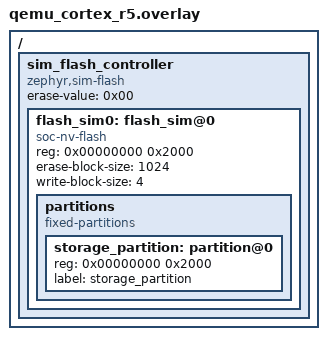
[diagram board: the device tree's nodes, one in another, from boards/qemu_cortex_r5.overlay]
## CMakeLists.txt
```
# Copyright (c) 2023 Intel Corporation.
# SPDX-License-Identifier: Apache-2.0

cmake_minimum_required(VERSION 3.28.0)
find_package(Zephyr REQUIRED HINTS $ENV{ZEPHYR_BASE})
project(llext_test)

target_sources(app PRIVATE
  src/test_llext.c
)

target_include_directories(app PRIVATE
  ${ZEPHYR_BASE}/include
  ${ZEPHYR_BASE}/kernel/include
  ${ZEPHYR_BASE}/arch/${ARCH}/include
)

set(ext_names
  hello_world
  logging
  relative_jump
  object
  syscalls
  inspect
  threads_kernel_objects
  export_dependent
  export_dependency
  align
)

if(CONFIG_ARM)
  if(NOT CONFIG_CPU_CORTEX_M0 AND NOT CONFIG_CPU_CORTEX_M0PLUS AND NOT CONFIG_CPU_CORTEX_M1)
    list(APPEND ext_names movwmovt)
  endif()
endif()

if(CONFIG_LLEXT_TYPE_ELF_RELOCATABLE AND NOT CONFIG_ARM)
    list(APPEND ext_names pre_located)
endif()

if(CONFIG_LLEXT_STORAGE_WRITABLE)
    list(APPEND ext_names find_section detached_fn)
endif()

if(NOT CONFIG_LLEXT_TYPE_ELF_SHAREDLIB)
    # ELF shared libraries do not support init sections
    list(APPEND ext_names init_fini)
endif()

if(CONFIG_LLEXT_RODATA_NO_RELOC AND NOT CONFIG_XTENSA)
    # Xtensa linker rejects relocations in .rodata even with -fPIC
    list(APPEND ext_names rodata_no_reloc)
endif()

if(CONFIG_XTENSA)
  # Only llext_link_plt(), used for all Xtensa relocations, accepts undefined weak symbols
  list(APPEND ext_names weak_undef)
endif()

# generate extension targets for each extension in 'ext_names'
foreach(ext_name ${ext_names})
  set(ext_src ${PROJECT_SOURCE_DIR}/src/${ext_name}_ext.c)
  set(ext_bin ${PROJECT_BINARY_DIR}/llext/${ext_name}.llext)
  set(ext_inc ${ZEPHYR_BINARY_DIR}/include/generated/${ext_name}.inc)
  add_llext_target(${ext_name}_ext
    OUTPUT  ${ext_bin}
    SOURCES ${ext_src}
  )
  generate_inc_file_for_target(app ${ext_bin} ${ext_inc})
endforeach()

if(CONFIG_LLEXT_VENEERS)
  set(ext_bin ${PROJECT_BINARY_DIR}/llext/veneer.llext)
  set(ext_inc ${ZEPHYR_BINARY_DIR}/include/generated/veneer.inc)
  add_llext_target(veneer_ext
    OUTPUT  ${ext_bin}
    SOURCES ${PROJECT_SOURCE_DIR}/src/veneer_ext.c
  )
  # -mno-long-calls overrides the global -mlong-calls so direct BL instructions
  # are emitted, producing R_ARM_THM_CALL relocations that exercise the veneer.
  get_target_property(veneer_lib veneer_ext lib_target)
  target_compile_options(${veneer_lib} PRIVATE -mno-long-calls)
  generate_inc_file_for_target(app ${ext_bin} ${ext_inc})
endif()

# C++ extensions exercising virtual dispatch, vtable relocations and weak
# symbols emitted for C++ code
if(CONFIG_CPP)
  function(add_cpp_llext_test ext_name)
    list(TRANSFORM ARGN PREPEND ${PROJECT_SOURCE_DIR}/src/)
    add_llext_target(${ext_name}_ext
      OUTPUT  ${PROJECT_BINARY_DIR}/llext/${ext_name}.llext
      SOURCES ${ARGN}
    )
    get_target_property(ext_lib ${ext_name}_ext lib_target)
    target_compile_options(${ext_lib} PRIVATE
      $<$<COMPILE_LANGUAGE:CXX>:-std=c++17>
      -fno-rtti
      -fno-exceptions
    )
    generate_inc_file_for_target(app ${PROJECT_BINARY_DIR}/llext/${ext_name}.llext
      ${ZEPHYR_BINARY_DIR}/include/generated/${ext_name}.inc
    )
  endfunction()

  add_cpp_llext_test(weak_vtable weak_vtable_ext.cpp)
  add_cpp_llext_test(cpp_dispatch cpp_dispatch_ext.cpp)
  add_cpp_llext_test(cpp_multi_tu cpp_multi_tu_ext1.cpp cpp_multi_tu_ext2.cpp)
endif()

# An extension referencing the thread-local errno, exercising the AArch64
# local-exec TLS relocations (R_AARCH64_TLSLE_ADD_TPREL_*). Only arm64
# implements these in arch_elf_relocate(); a libc whose errno is genuinely
# __thread (toolchain picolibc with thread-local storage) is enabled by the
# llext.tls scenario.
if(CONFIG_ARM64 AND CONFIG_THREAD_LOCAL_STORAGE)
  add_llext_target(tls_ext
    OUTPUT  ${PROJECT_BINARY_DIR}/llext/tls.llext
    SOURCES ${PROJECT_SOURCE_DIR}/src/tls_ext.c
  )
  generate_inc_file_for_target(app ${PROJECT_BINARY_DIR}/llext/tls.llext
    ${ZEPHYR_BINARY_DIR}/include/generated/tls.inc
  )
endif()

if(NOT CONFIG_LLEXT_TYPE_ELF_OBJECT)
  add_llext_target(multi_file_ext
    OUTPUT  ${PROJECT_BINARY_DIR}/llext/multi_file.llext
    SOURCES ${PROJECT_SOURCE_DIR}/src/multi_file_ext1.c ${PROJECT_SOURCE_DIR}/src/multi_file_ext2.c
  )
  generate_inc_file_for_target(app ${PROJECT_BINARY_DIR}/llext/multi_file.llext
    ${ZEPHYR_BINARY_DIR}/include/generated/multi_file.inc
  )
endif()

get_property(TOPT GLOBAL PROPERTY TOPT)
get_property(COMPILER_TOPT TARGET compiler PROPERTY linker_script)
set_ifndef(  TOPT "${COMPILER_TOPT}")
set_ifndef(  TOPT -Wl,-T) # Use this if the compiler driver doesn't set a value

if(CONFIG_LLEXT_TYPE_ELF_RELOCATABLE AND CONFIG_XTENSA AND CONFIG_LLEXT_STORAGE_WRITABLE)
  # Manually fix the pre_located extension's text address at a multiple of 4
  get_target_property(pre_located_target pre_located_ext lib_target)
  get_target_property(pre_located_file pre_located_ext pkg_input)
  add_llext_command(
    TARGET pre_located_ext
    POST_BUILD
    COMMAND ${CMAKE_C_COMPILER}
    ${LLEXT_APPEND_FLAGS}
    -Wl,-r ${TOPT}text=0xbada110c -nostdlib -nodefaultlibs -nostartfiles
    $<TARGET_OBJECTS:${pre_located_target}> -o ${pre_located_file}
  )
endif()

if(CONFIG_LLEXT_TYPE_ELF_RELOCATABLE AND CONFIG_XTENSA)
  # A copy of hello_world with a relocation offset past the end of .text
  set(ext_bin ${PROJECT_BINARY_DIR}/llext/reloc_offset_oob.llext)
  add_custom_command(
    OUTPUT ${ext_bin}
    COMMAND ${PYTHON_EXECUTABLE} ${PROJECT_SOURCE_DIR}/reloc_offset_oob.py
            ${PROJECT_BINARY_DIR}/llext/hello_world.llext ${ext_bin}
    DEPENDS ${PROJECT_BINARY_DIR}/llext/hello_world.llext
            ${PROJECT_SOURCE_DIR}/reloc_offset_oob.py
  )
  generate_inc_file_for_target(app ${ext_bin}
    ${ZEPHYR_BINARY_DIR}/include/generated/reloc_offset_oob.inc
  )
endif()

if(NOT CONFIG_LLEXT_TYPE_ELF_OBJECT AND CONFIG_RISCV AND CONFIG_RISCV_ISA_EXT_C)
  add_llext_target(riscv_edge_case_cb_type_ext
    OUTPUT  ${PROJECT_BINARY_DIR}/llext/riscv_edge_case_cb_type_ext.llext
    SOURCES ${PROJECT_SOURCE_DIR}/src/riscv_edge_case_cb_type.c ${PROJECT_SOURCE_DIR}/src/riscv_edge_case_cb_type_trigger.S
  )
  generate_inc_file_for_target(app ${PROJECT_BINARY_DIR}/llext/riscv_edge_case_cb_type_ext.llext
    ${ZEPHYR_BINARY_DIR}/include/generated/riscv_edge_case_cb_type.inc
  )
endif()

if(NOT CONFIG_LLEXT_TYPE_ELF_OBJECT AND CONFIG_RISCV)
  add_llext_target(riscv_edge_case_non_paired_hi20_lo12_ext
    OUTPUT  ${PROJECT_BINARY_DIR}/llext/riscv_edge_case_non_paired_hi20_lo12_ext.llext
    SOURCES ${PROJECT_SOURCE_DIR}/src/riscv_edge_case_non_paired_hi20_lo12.c ${PROJECT_SOURCE_DIR}/src/riscv_edge_case_non_paired_hi20_lo12_trigger.S
  )
  generate_inc_file_for_target(app ${PROJECT_BINARY_DIR}/llext/riscv_edge_case_non_paired_hi20_lo12_ext.llext
    ${ZEPHYR_BINARY_DIR}/include/generated/riscv_edge_case_non_paired_hi20_lo12.inc
  )
endif()
```

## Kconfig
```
# SPDX-License-Identifier: Apache-2.0
# Copyright (c) 2025 Intel Corporation.

mainmenu "LLEXT tests"

config MP_MAX_NUM_CPUS
	default 1 if LLEXT_READONLY_1CPU

source "Kconfig.zephyr"

config LLEXT_INC_IN_TEXT
	bool "Put extension .inc array in .text instead of .data"
	help
	  Put the llext extension .inc arrays from the LLEXT subsys tests
	  in .text instead of .data by default. This is useful for when the
	  memory region the linker places .data in by default is not suitable
	  for execution.

config LLEXT_READONLY_1CPU
	bool "Enable this when using readonly elf buffer on 1 CPU"
	depends on SOC_SERIES_INTEL_ADSP_ACE20 || \
		SOC_SERIES_INTEL_ADSP_ACE30 || \
		SOC_SERIES_INTEL_ADSP_ACE40
	select LLEXT_CUSTOM_HEAP_PLACEMENT
```

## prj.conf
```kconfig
CONFIG_ZTEST=y
CONFIG_ZTEST_STACK_SIZE=4096
CONFIG_LOG=y
CONFIG_LLEXT=y
CONFIG_LLEXT_HEAP_SIZE=64
CONFIG_LLEXT_EXPORT_DEVICES=y

CONFIG_APPLICATION_DEFINED_SYSCALL=y

# RISC-V copies the loaded extension into RAM and runs it in machine
# mode, so the loaded text must stay executable. Data execution
# prevention installs a locked catch-all PMP entry that makes all RAM
# non-executable, which faults on the first call into an extension.
# Setting an unknown symbol to 'n' has no effect, so this is safe on
# the other architectures.
CONFIG_PMP_DATA_EXECUTION_PREVENTION=n

# The bulk of the tests run with MPU/MMU disabled by including additional
# configuration entries from no_mem_protection.conf.
```

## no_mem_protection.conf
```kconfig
# Disable MPU and MMU on all supported arches for the bulk of the tests.
#
# This uses the fact that setting an unknown symbol to 'n' has no effect,
# so it is safe to group different arch-specific settings here.
#
CONFIG_ARM_MPU=n
CONFIG_ARM_AARCH32_MMU=n
CONFIG_RISCV_PMP=n
CONFIG_ARC_MPU_ENABLE=n
CONFIG_X86_MMU=n
```

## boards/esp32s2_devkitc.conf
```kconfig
CONFIG_SYS_HEAP_BIG_ONLY=y
```

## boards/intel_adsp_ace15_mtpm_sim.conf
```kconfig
# xt-clang cannot link shared libs for xtensa
CONFIG_LLEXT_TYPE_ELF_RELOCATABLE=y
```

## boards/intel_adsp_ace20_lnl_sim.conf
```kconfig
# xt-clang cannot link shared libs for xtensa
CONFIG_LLEXT_TYPE_ELF_RELOCATABLE=y
CONFIG_LLEXT_INC_IN_TEXT=y
```

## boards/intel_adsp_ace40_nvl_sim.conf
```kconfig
# xt-clang cannot link shared libs for xtensa
CONFIG_LLEXT_TYPE_ELF_RELOCATABLE=y
CONFIG_LLEXT_INC_IN_TEXT=y
CONFIG_LLEXT_CUSTOM_HEAP_PLACEMENT=y
```

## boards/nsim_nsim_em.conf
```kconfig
CONFIG_LLEXT_INSTR_HEAP_SIZE=16
CONFIG_LLEXT_DATA_HEAP_SIZE=48
```

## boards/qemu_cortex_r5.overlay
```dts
/ {
	sim_flash_controller: sim_flash_controller {
		compatible = "zephyr,sim-flash";

		#address-cells = <1>;
		#size-cells = <1>;
		erase-value = <0x00>;

		flash_sim0: flash_sim@0 {
			compatible = "soc-nv-flash";
			reg = <0x00000000 0x2000>;

			erase-block-size = <1024>;
			write-block-size = <4>;

			partitions {
				compatible = "fixed-partitions";
				#address-cells = <1>;
				#size-cells = <1>;

				storage_partition: partition@0 {
					reg = <0x00000000 0x2000>;
					label = "storage_partition";
				};
			};
		};
	};
};
```

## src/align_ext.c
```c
/*
 * Copyright (c) 2025 Arduino SA
 *
 * SPDX-License-Identifier: Apache-2.0
 */

/*
 * Define symbols with different alignment requirements and verify that LLEXT
 * correctly handles them by testing the runtime address and the contents of
 * each defined symbol.
 */

#include <stdint.h>
#include <zephyr/kernel.h>
#include <zephyr/llext/symbol.h>
#include <zephyr/ztest_assert.h>

/*
 * Create constants requesting a specific alignment in memory and with a value
 * that is related but not equal to their alignment requirement.
 */
#define ALIGNED_ENTRY(name, n) \
	 const int name ## _ ## n __aligned(n) = n / 2 + 1

ALIGNED_ENTRY(common, 8);
ALIGNED_ENTRY(common, 16);
ALIGNED_ENTRY(common, 32);
ALIGNED_ENTRY(common, 64);
ALIGNED_ENTRY(common, 128);
ALIGNED_ENTRY(common, 256);
ALIGNED_ENTRY(common, 512);

/*
 * Create similar constants in a set of independent sections to test merging.
 */
#define ALIGNED_SECT_ENTRY(name, n) \
	Z_GENERIC_SECTION(name ## _sect_ ## n) ALIGNED_ENTRY(name, n)

ALIGNED_SECT_ENTRY(independent, 8);
ALIGNED_SECT_ENTRY(independent, 16);
ALIGNED_SECT_ENTRY(independent, 32);
ALIGNED_SECT_ENTRY(independent, 64);
ALIGNED_SECT_ENTRY(independent, 128);
ALIGNED_SECT_ENTRY(independent, 256);
ALIGNED_SECT_ENTRY(independent, 512);

/*
 * Test that each symbol matches its expected value and alignment.
 */
#define ASSERT_ENTRY(name, n) \
	zassert_equal(name ## _ ## n, n / 2 + 1); \
	zassert_true(IS_ALIGNED(&name ## _ ## n, n))

void test_entry(void)
{
	ASSERT_ENTRY(common, 8);
	ASSERT_ENTRY(common, 16);
	ASSERT_ENTRY(common, 32);
	ASSERT_ENTRY(common, 64);
	ASSERT_ENTRY(common, 128);
	ASSERT_ENTRY(common, 256);
	ASSERT_ENTRY(common, 512);

	ASSERT_ENTRY(independent, 8);
	ASSERT_ENTRY(independent, 16);
	ASSERT_ENTRY(independent, 32);
	ASSERT_ENTRY(independent, 64);
	ASSERT_ENTRY(independent, 128);
	ASSERT_ENTRY(independent, 256);
	ASSERT_ENTRY(independent, 512);
}
EXPORT_SYMBOL(test_entry);
```

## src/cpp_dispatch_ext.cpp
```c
/*
 * Copyright (c) 2026 Intel Corporation.
 *
 * SPDX-License-Identifier: Apache-2.0
 */

/*
 * Virtual dispatch with multiple inheritance, which needs secondary vtable
 * pointers and this-adjusting thunks, and through an abstract interface
 * returned by a factory function, the usual shape of a C++ module.
 */

#include <zephyr/llext/symbol.h>
#include <zephyr/ztest_assert.h>
#include "cpp_ext.hpp"

class Left {
public:
	virtual int left() const { return 1; }
};

class Right {
public:
	virtual int right() const { return 2; }
};

class Both : public Left, public Right {
public:
	int left() const override { return 10; }
	int right() const override { return 20; }
};

class Iface {
public:
	virtual int run(int x) const = 0;
	virtual int id() const = 0;
};

class Impl : public Iface {
public:
	int run(int x) const override { return x + 100; }
	int id() const override { return 3; }
};

/* Constant-initialized, so the vtable pointers are relocated data */
static Both global_both;
static Impl impl;

__attribute__((noinline)) Iface *cpp_dispatch_create(void)
{
	return &impl;
}

static void check_both(const Both *both)
{
	const Left *l = opaque(static_cast<const Left *>(both));
	const Right *r = opaque(static_cast<const Right *>(both));

	zassert_not_equal((const void *)r, (const void *)both,
			  "Right should be a non-primary base");
	zassert_equal(l->left(), 10, "left() returned %d", l->left());
	zassert_equal(r->right(), 20, "right() returned %d", r->right());
}

extern "C" void test_entry(void)
{
	Both local_both;
	Iface *iface = opaque(cpp_dispatch_create());

	check_both(&global_both);
	check_both(&local_both);

	zassert_equal(iface->run(1), 101, "run() returned %d", iface->run(1));
	zassert_equal(iface->id(), 3, "id() returned %d", iface->id());
}
EXPORT_SYMBOL(test_entry);
```

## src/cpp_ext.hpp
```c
/*
 * Copyright (c) 2026 Intel Corporation.
 *
 * SPDX-License-Identifier: Apache-2.0
 */

#ifndef LLEXT_TEST_CPP_EXT_HPP
#define LLEXT_TEST_CPP_EXT_HPP

/* Hide the dynamic type from the compiler, so calls go through the vtable */
template <typename T> static inline T *opaque(T *p)
{
	__asm__ volatile("" : "+r"(p));
	return p;
}

#endif /* LLEXT_TEST_CPP_EXT_HPP */
```

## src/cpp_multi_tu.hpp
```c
/*
 * Copyright (c) 2026 Intel Corporation.
 *
 * SPDX-License-Identifier: Apache-2.0
 */

#ifndef LLEXT_TEST_CPP_MULTI_TU_HPP
#define LLEXT_TEST_CPP_MULTI_TU_HPP

class Shape {
public:
	/* Key function: the vtable is emitted only in cpp_multi_tu_ext2.cpp */
	virtual int area() const;
	virtual int sides() const { return 0; }
};

class Square : public Shape {
public:
	explicit Square(int s) : side(s) {}
	int area() const override;
	int sides() const override { return 4; }

private:
	int side;
};

/* No key function: vtable and members are weak copies in both files */
template <typename T> class Box {
public:
	explicit Box(T v) : val(v) {}
	virtual T get() const { return val; }

private:
	T val;
};

template <typename T> __attribute__((noinline)) T twice(T v)
{
	return v * 2;
}

int box_twice_in_ext2(int v);

#endif /* LLEXT_TEST_CPP_MULTI_TU_HPP */
```

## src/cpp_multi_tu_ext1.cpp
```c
/*
 * Copyright (c) 2026 Intel Corporation.
 *
 * SPDX-License-Identifier: Apache-2.0
 */

/*
 * C++ extension built from two files: virtual dispatch through a vtable
 * defined in the other file, and template code instantiated in both.
 */

#include <zephyr/llext/symbol.h>
#include <zephyr/ztest_assert.h>
#include "cpp_ext.hpp"
#include "cpp_multi_tu.hpp"

extern "C" void test_entry(void)
{
	Square square(3);
	Shape *shape = opaque(static_cast<Shape *>(&square));
	Box<int> box(5);

	zassert_equal(shape->area(), 9, "area() returned %d", shape->area());
	zassert_equal(shape->sides(), 4, "sides() returned %d", shape->sides());
	zassert_equal(twice(opaque(&box)->get()), 10, "Box<int> in ext1 failed");
	zassert_equal(box_twice_in_ext2(7), 14, "Box<int> in ext2 failed");
}
EXPORT_SYMBOL(test_entry);
```

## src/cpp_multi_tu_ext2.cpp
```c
/*
 * Copyright (c) 2026 Intel Corporation.
 *
 * SPDX-License-Identifier: Apache-2.0
 */

#include "cpp_ext.hpp"
#include "cpp_multi_tu.hpp"

int Shape::area() const
{
	return 0;
}

int Square::area() const
{
	return side * side;
}

int box_twice_in_ext2(int v)
{
	Box<int> box(v);

	return twice(opaque(&box)->get());
}
```

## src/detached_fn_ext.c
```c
/*
 * Copyright (c) 2024 Intel Corporation.
 *
 * SPDX-License-Identifier: Apache-2.0
 */

#include <stdint.h>
#include <zephyr/llext/symbol.h>
#include <zephyr/sys/printk.h>
#include <zephyr/ztest_assert.h>

Z_GENERIC_SECTION(.detach) void detached_entry(void)
{
	static int data_cnt = -3;
	static unsigned int bss_cnt;

	printk("bss %u @ %p\n", bss_cnt++, &bss_cnt);
	printk("data %d @ %p\n", data_cnt++, &data_cnt);
	zassert_true(data_cnt < 0);
	zassert_true(bss_cnt < 3);
}
EXPORT_SYMBOL(detached_entry);

void test_entry(void)
{
	detached_entry();
}
EXPORT_SYMBOL(test_entry);
```

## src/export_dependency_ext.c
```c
/*
 * Copyright (c) 2024 Intel Corporation.
 *
 * SPDX-License-Identifier: Apache-2.0
 */

/* Test exporting symbols, imported by other LLEXTs */

#include <zephyr/llext/symbol.h>

long test_dependency(int a, int b)
{
	return (long)a * b;
}
EXPORT_SYMBOL(test_dependency);
```

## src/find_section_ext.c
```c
/*
 * Copyright (c) 2024 Arduino SA
 *
 * SPDX-License-Identifier: Apache-2.0
 */

/* This very basic extension only contains a global variable "number", which is
 * expected to be mapped at offset 0 in the .data section. This can be used in
 * CONFIG_LLEXT_STORAGE_WRITABLE-enabled builds to verify that the variable
 * address, as calculated by the llext loader, matches the start of the .data
 * section in the ELF buffer as returned by llext_find_section.
 *
 * If only this test fails, the llext_find_section API is likely broken.
 */

#include <zephyr/llext/symbol.h>

int number = 42;

void test_entry(void)
{
	/* unused */
}

EXPORT_SYMBOL(number);
```

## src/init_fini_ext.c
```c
/*
 * Copyright (c) 2024 Arduino SA
 *
 * SPDX-License-Identifier: Apache-2.0
 */

/*
 * This test checks for proper support of ELF init arrays. This processing is
 * performed by llext_bootstrap(), which gets the function pointers from LLEXT
 * via the llext_get_fn_table_entry() syscall.
 *
 * Each function in this test shifts the number left by 4 bits and sets the
 * lower 4 bits to a specific value. The proper init sequence (preinit_fn_1,
 * preinit_fn_2, init_fn) would leave number set to 0x123; the termination
 * function will further shift the number to 0x1234. If a different result is
 * detected, then either not all routines were executed, or their order was not
 * correct.
 */

#include <stdint.h>
#include <zephyr/llext/symbol.h>
#include <zephyr/toolchain.h>
#include <zephyr/sys/printk.h>
#include <zephyr/ztest_assert.h>

static int number;
EXPORT_SYMBOL(number);

static void preinit_fn_1(void)
{
	number = 1;
}

static void preinit_fn_2(void)
{
	number <<= 4;
	number |= 2;
}

static void init_fn(void)
{
	number <<= 4;
	number |= 3;
}

static void fini_fn(void)
{
	number <<= 4;
	number |= 4;
}

static const void *const preinit_fn_ptrs[] __used Z_GENERIC_SECTION(.preinit_array) = {
	preinit_fn_1,
	preinit_fn_2
};
static const void *const init_fn_ptrs[] __used Z_GENERIC_SECTION(.init_array) = {
	init_fn
};
static const void *const fini_fn_ptrs[] __used Z_GENERIC_SECTION(.fini_array) = {
	fini_fn
};

void test_entry(void)
{
	/* fini_fn() is not called yet, so we expect 0x123 here */
	const int expected = (((1 << 4) | 2) << 4) | 3;

	zassert_equal(number, expected, "got 0x%x instead of 0x%x during test",
		      number, expected);
}
EXPORT_SYMBOL(test_entry);
```

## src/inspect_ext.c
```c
/*
 * Copyright (c) 2025 Arduino SA
 *
 * SPDX-License-Identifier: Apache-2.0
 */

/* This extension exports a number of symbols to be used by the LLEXT
 * inspection APIs. Each symbol is exported within a different section
 * and only the addresses are checked in this test.
 */

#include <zephyr/llext/symbol.h>

int number_in_bss;
int number_in_data = 1;
const int number_in_rodata = 2;
const int number_in_my_rodata Z_GENERIC_SECTION(.my_rodata) = 3;

void function_in_text(void)
{
	/* only used for address check */
}

EXPORT_SYMBOL(number_in_bss);
EXPORT_SYMBOL(number_in_data);
EXPORT_SYMBOL(number_in_rodata);
EXPORT_SYMBOL(number_in_my_rodata);
EXPORT_SYMBOL(function_in_text);
```

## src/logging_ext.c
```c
/*
 * Copyright (c) 2023 Intel Corporation.
 *
 * SPDX-License-Identifier: Apache-2.0
 */

/*
 * This very simple hello world C code can be used as a test case for building
 * probably the simplest loadable extension. It requires a single symbol be
 * linked, section relocation support, and the ability to export and call out to
 * a function.
 */

#include <stdint.h>
#include <zephyr/llext/symbol.h>
#include <zephyr/logging/log.h>
LOG_MODULE_REGISTER(logging_ext);

static const uint32_t number = 42;

void test_entry(void)
{
	LOG_INF("hello world");
	LOG_INF("A number is %" PRIu32, number);
}
EXPORT_SYMBOL(test_entry);
```
